# RL6845_IP_SVD register map
Vendor: Realtek
Registers are 32-bit, read-write, reset 0x0 unless marked. A register's access mark holds for its fields unless they carry their own. Offsets are from the block's base; [hi:lo] are bit positions; lines under a group give offsets from that group; {n}, {i} and the like mark numbered series.

## lp_aon
Base 0x41008000
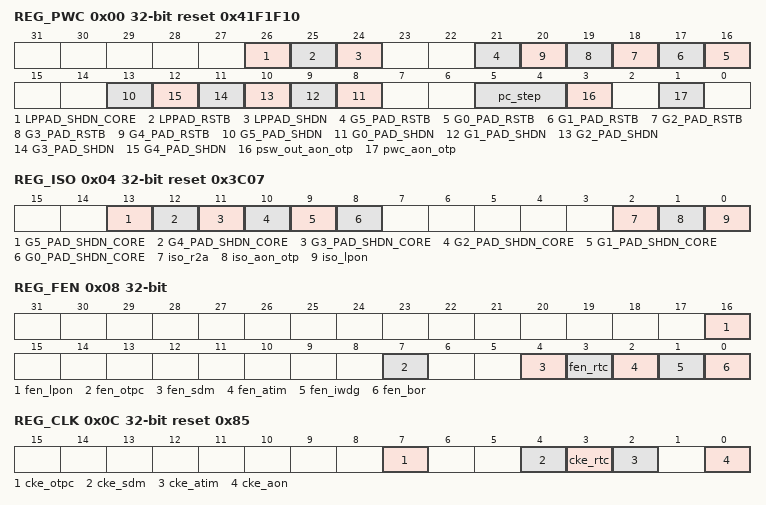
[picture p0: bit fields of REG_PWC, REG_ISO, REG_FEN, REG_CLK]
0x00 REG_PWC access per field reset 0x41F1F10
  [26] LPPAD_SHDN_CORE rw — 1: Release LP PAD SHDN CORE (except G5) 0: Global Assert LP PAD RSTB33 Note:G5 is aon pad, when all LP pad's IO power is ready , aon pmc will release this bit , only in power on init seq .
  [25] LPPAD_RSTB rw — 1: Release LP PAD RSTB33 (except G5) 0: Global Assert LP PAD RSTB33 Note: aon pmc will auto release this bit in power on init seq
  [24] LPPAD_SHDN rw — 1: Global Enable LP PAD (except G5) 0: Shutdown LP PAD Note: aon pmc will auto release this bit in power on init seq
  [21] G5_PAD_RSTB rw — 1: Enable G5 group pad 0: Reset PAD Note: This is AON pad group, direct connect to G5 pad, aon pmc will auto release this bit in power on init seq
  [n+16] G{n}_PAD_RSTB rw (n=0..4) — 1: Enable G{n} group pad 0: Reset PAD
  [13] G5_PAD_SHDN rw — 1: Enable G5 group pad 0: Shutdown PAD Note: This is AON pad group, aon pmc will auto release this bit in power on init seq
  [n+8] G{n}_PAD_SHDN rw (n=0..4) — 1: Enable G{n} group pad 0: Shutdown PAD
  [5:4] pc_step rw — power cut enable time step. 0: not valid 1: 10us 2: 20us 3: 30us
  [3] psw_out_aon_otp ro — aon otp domain power switch status 1: power on 0: power off
  [1] pwc_aon_otp rw — OTP power cut enable for core power, high active. 1:enable 0:disable
0x04 REG_ISO reset 0x3C07
  [13] G5_PAD_SHDN_CORE — 1: Enable G5 group pad 0: Shutdown PAD Note: This maybe nouse , for AON pad , IO power always on before core power.
  [12] G4_PAD_SHDN_CORE — 1: Enable G4 group pad 0: Shutdown PAD
  [11] G3_PAD_SHDN_CORE — 1: Enable G3 group pad 0: Shutdown PAD
  [10] G2_PAD_SHDN_CORE — 1: Enable G2 group pad 0: Shutdown PAD
  [9] G1_PAD_SHDN_CORE — 1: Enable G1 group pad 0: Shutdown PAD Note:default is shutdown, wait pmc enable MLDO power
  [8] G0_PAD_SHDN_CORE — 1: Enable G0 group pad 0: Shutdown PAD
  [2] iso_r2a — 1: ISO signals from RTC to AON 0: Release
  [1] iso_aon_otp — 1: ISO signals from otp core power domain 0: Release
  [0] iso_lpon — When LDO core power on, PD_LPON is on. 1: ISO signal of LPON power domain 0: Release
0x08 REG_FEN
  [16] fen_lpon — LS global reset 1: Enable LS function 0: Disable
  [7] fen_otpc — 1: Enable OTP function 0: Disable
  [4] fen_sdm — 1: Enable 32.768K SDM function 0: Disable
  [3] fen_rtc — 1: Enable RTC function 0: Disable
  [2] fen_atim — 1: Enable AON timer 0: Reset AON timer Note: AON timer starts to run only when event happens.
  [1] fen_iwdg — 1: Enable IWDG by HW autoload. Once enabled, IWDG can't be disabled unless por asserts.
  [0] fen_bor — Enable bor reset function, default is 0 when power on
0x0C REG_CLK reset 0x85
  [7] cke_otpc — 1: Enable OTPC clock 0: Disable Note: default change to 1 for osc4m req
  [4] cke_sdm — 1: Enable 32.768K SDM module's clock 0: Disable
  [3] cke_rtc — 1: Enable RTC clock 0: Disable
  [2] cke_atim — 1: Enable AON timer clock 0: Disable
  [0] cke_aon — if 0, AON clock will be gated except atim and debouce circuit. Note: AON clock can't be shutdown as analog need.
0x10 REG_CKSL
  [0] otpc_flg — This field is used to indicate OTP autoload field 1: ls 0:aon Note:because aon autoload only do once , so after power on , this bit will always be 1 . SW don't change this bit .
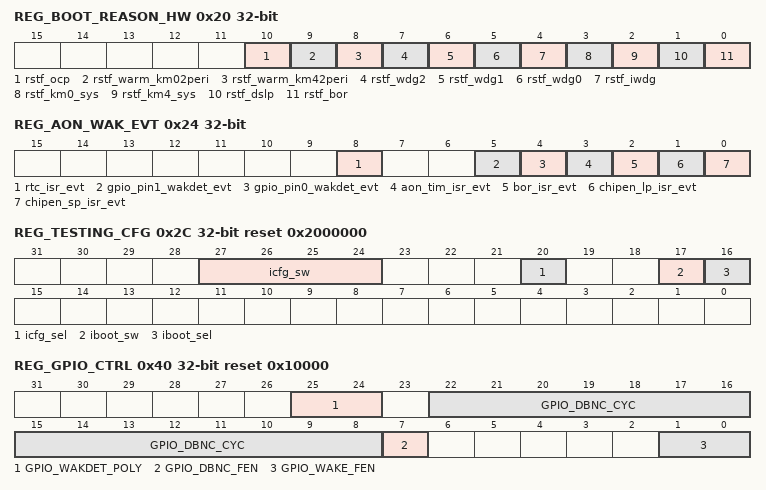
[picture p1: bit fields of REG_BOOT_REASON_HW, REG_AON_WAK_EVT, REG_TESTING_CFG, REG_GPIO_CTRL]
0x20 REG_BOOT_REASON_HW ro
  [10] rstf_ocp — This bit will be set to 1 when OCP happen, it will let system enter dslp mode. Write 1 to clear.
  [9] rstf_warm_km02peri — This bit will be set to 1 when KM0 warm resets the system. Write 1 to clear.
  [8] rstf_warm_km42peri — This bit will be set to 1 when km4 warm resets the system. Write 1 to clear.
  [7] rstf_wdg2 — This bit will be set to 1 when WDG resets the system. Write 1 to clear.
  [6] rstf_wdg1 — This bit will be set to 1 when WDG resets the system. Write 1 to clear.
  [5] rstf_wdg0 — This bit will be set to 1 when WDG resets the system. Write 1 to clear.
  [4] rstf_iwdg — This bit will be set to 1 when WDG resets the system. Write 1 to clear.
  [3] rstf_km0_sys — This bit will be set to 1 when KM0 resets the system. Write 1 to clear.
  [2] rstf_km4_sys — This bit will be set to 1 when KM4 resets the system. Write 1 to clear.
  [1] rstf_dslp — This is boot reason for dslp exit, clear by SW write to 1.
  [0] rstf_bor — This bit will be set to 1 when BOR resets the system. Write 1 to clear.
0x24 REG_AON_WAK_EVT ro
  [8] rtc_isr_evt — RTC interrupt wake event occurs.
  [5] gpio_pin1_wakdet_evt — Wake event for wake pin1 1: wake event detected 0: no wake event Note: aon gpio only used to wake hw pmc, to interrupt SW, it must enable GPIO interrupt in LP GPIO IP, and the poly must be same as AON GPIO setting.
  [4] gpio_pin0_wakdet_evt — Wake event for wake pin0 1: wake event detected 0: no wake event Note: aon gpio only used to wake hw pmc, to interrupt SW, it must enable GPIO interrupt in LP GPIO IP, and the poly must be same as AON GPIO setting.
  [3] aon_tim_isr_evt — AON timer interrupt event occurs.
  [2] bor_isr_evt — bor interrupt event occurs.
  [1] chipen_lp_isr_evt — Chipen long press interrupt event occurs.
  [0] chipen_sp_isr_evt — Chipen short press interrupt event occurs.
0x2C REG_TESTING_CFG reset 0x2000000
  [27:24] icfg_sw — icfg configured by SIC/SW
  [20] icfg_sel — If 1, using icfg_sw to replace trapped icfg value.
  [17] iboot_sw — iboot configured by SIC/SW
  [16] iboot_sel — If 1, using iboot_sw to replace trapped iboot value.
0x30 REG_TIM_CNT ro
  [31:0] aon_tim_cnt_cur — Aon timer current count value.
0x34 REG_TIM_SET
  [31:0] aon_tim_cnt_set — Set aon time a countdown value, when timer count down, it will trigger a aon_tim event.
0x38 REG_TIM_IER
  [0] AON_TIM_IE — Timer interrupt enable 0:disable 1:enable
0x3C REG_TIM_ISR ro
  [0] AON_TIM_ISR — Timer interrupt status 0:no interrupt 1:interrupt occurs
0x40 REG_GPIO_CTRL reset 0x10000
  [25:24] GPIO_WAKDET_POLY — Wake pin polarity 0: low active 1: high active bit1: wake pin1 polarity bit0: wake pin0 polarity Note: once a wake pin is set, the pads PU/PD will be force by this poly value, and soft config have no use.
  [22:8] GPIO_DBNC_CYC — The GPIO signal will be filtered by the number of debounce cycles of specified in this register. (100k/128k)
  [7] GPIO_DBNC_FEN — 1: Enable gpio debouncer function 0: Disable Default disable for simualtion issue
  [1:0] GPIO_WAKE_FEN — 1: Enable wake pin function 0: Disable Every GPIO has its own enable. When aon pmc is not in DSLP, wake pins will not effect PMC state althrougth this bit is set.
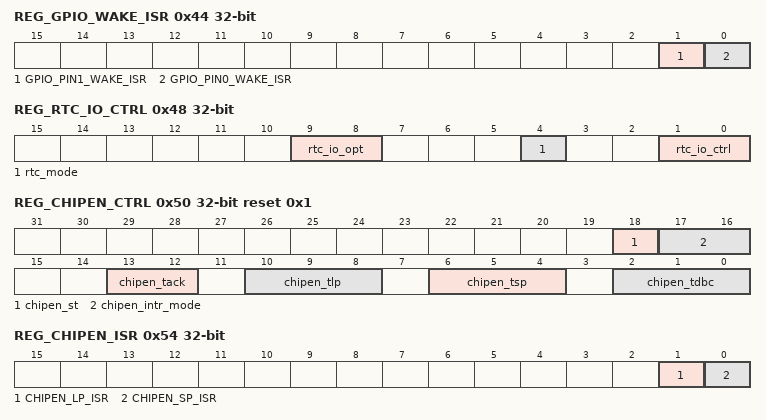
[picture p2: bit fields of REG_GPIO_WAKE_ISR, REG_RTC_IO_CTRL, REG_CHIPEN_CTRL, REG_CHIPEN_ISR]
0x44 REG_GPIO_WAKE_ISR ro
  [1] GPIO_PIN1_WAKE_ISR — Wake pin1 interrupt status 0:no interrupt 1:interrupt occurs
  [0] GPIO_PIN0_WAKE_ISR — Wake pin0 interrupt status 0:no interrupt 1:interrupt occurs
0x48 REG_RTC_IO_CTRL access per field
  [9:8] rtc_io_opt rw — RTC IO option register [0]: extend diode [1]: rsvd
  [4] rtc_mode ro — RTC IO mode flag 1: RTC IO domain enabled 0: disable
  [1:0] rtc_io_ctrl rw — RTC IO control mode 0: shift disable 1: shift enable 2: rtc mode (once enable , it can't be disabled) 3: iwdg feed
0x4C REG_IWDG_IO_DIS reset 0x1
  [0] iwdg_io_dis — IWDG IO disable . Default enabled in RTC domain . This bit is protected , and only can be accessed by OTP
0x50 REG_CHIPEN_CTRL access per field reset 0x1
  [18] chipen_st ro — CHIP_EN pin status 0: logic '0' on CHIP_EN pin 1: logic '1' on CHIP_EN pin
  [17:16] chipen_intr_mode rw — Chipen operation mode. 00: reset mode. When chipen pad low, hw will reset all chip 01: interrup mode. It will enable short/long press function. 1X: pulse reset mode. The transation from other value to 2'd2 will gen a posedge to set RST_PULSE_EN in HV domain. Once in pulse reset mode , this field can't be modified again , and always read out 2'b11
  [13:12] chipen_tack rw — 00: 50ms 01: 100ms 10: 200ms 11: 400ms
  [10:8] chipen_tlp rw — 000: 1000ms 001: 1500ms 010: 2000ms 011: 2500ms 100: 3000ms 101: 3500ms 110: 4000ms 111: 4500ms
  [6:4] chipen_tsp rw — 000: 0ms 001: 50ms 010: 100ms 011: 150ms 100: 200ms 101: 250ms 110: 300ms 111: 350ms
  [2:0] chipen_tdbc rw — 000: 0us 001: 100us 010: 500us 011: 1000us 100: 2000us 101: 4000us 110: 8000us 111: 16000us
0x54 REG_CHIPEN_ISR ro
  [1] CHIPEN_LP_ISR — chipen long press interrupt status 0:no interrupt 1:interrupt occurs
  [0] CHIPEN_SP_ISR — chipen short press interrupt status 0:no interrupt 1:interrupt occurs
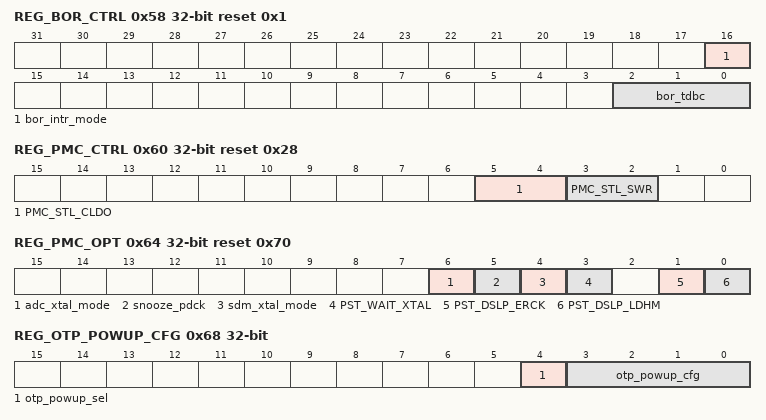
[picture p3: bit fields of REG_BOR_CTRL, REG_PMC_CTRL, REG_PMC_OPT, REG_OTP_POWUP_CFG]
0x58 REG_BOR_CTRL reset 0x1
  [16] bor_intr_mode — BOR operation mode. 0: reset mode. When analog detect bor, hw will trigger a bor reset. 1: interrup mode. It will raise an interrup first. If this bit set to 0, then trigger a bor reset.
  [2:0] bor_tdbc — 000: 0us 001: 100us 010: 500us 011: 1000us 100: 2000us 101: 4000us 110: 8000us 111: 16000us
0x5C REG_BOR_ISR ro
  [0] BOR_ISR — BOR interrupt status 0:no interrupt 1:interrupt occurs
0x60 REG_PMC_CTRL reset 0x28
  [5:4] PMC_STL_CLDO — wait time for core LDO stable 0: 8*T (T = 10us) 1: 16*T 2: 32*T 3: 64*T
  [3:2] PMC_STL_SWR — wait time for SWR stable 0: 64*T (T = 10us) 1: 128*T 2: 256*T 3: 512*T
0x64 REG_PMC_OPT reset 0x70
  [6] adc_xtal_mode — Select xtal mode when xtal used for adc/ctc/comp. 1: Normal 0: LPS
  [5] snooze_pdck — Select xtal auto pdck function for sdm calibration use xtal lps mode 1:Enable 0:Disable
  [4] sdm_xtal_mode — Select xtal mode when xtal used for sdm calibration. 1: Normal 0: LPS
  [3] PST_WAIT_XTAL — 1: When POF , polling xtal invalid signal and then run forward 0: not polling xtal invalid
  [1] PST_DSLP_ERCK — 1: Enable 100K clock for AON register access when PMC enter deep-sleep mode 0: Disable
  [0] PST_DSLP_LDHM — 1: Enable AON LDO enter into sleep mode when PMC enter deep-sleep mode 0: Disable
0x68 REG_OTP_POWUP_CFG
  [4] otp_powup_sel — select otp pow up flow is inside control or outside control 0: inside 1: outside
  [3:0] otp_powup_cfg — [0] : penvddr2 [1]: pldo [2]: pdstb [3]: ptrim
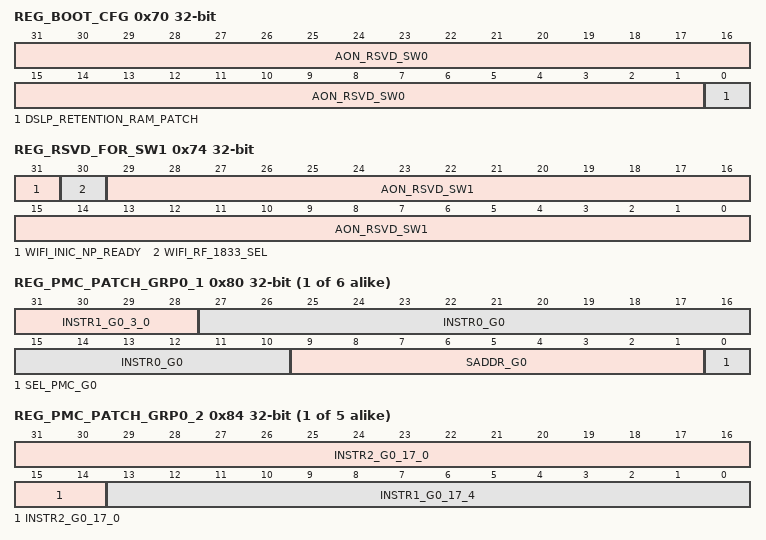
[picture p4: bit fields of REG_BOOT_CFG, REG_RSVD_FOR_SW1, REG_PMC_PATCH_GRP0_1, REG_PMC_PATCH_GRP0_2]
0x70 REG_BOOT_CFG
  [31:1] AON_RSVD_SW0
  [0] DSLP_RETENTION_RAM_PATCH — Deepsleep retention RAM patch
0x74 REG_RSVD_FOR_SW1
  [31] WIFI_INIC_NP_READY — Wi-Fi NP initialization ready flag
  [30] WIFI_RF_1833_SEL — Indication of RF voltage selection 0: 1.8V 1: 3.3V
  [29:0] AON_RSVD_SW1
{0x80+8i} REG_PMC_PATCH_GRP{i}_1 (i=0..5)
  [31:28] INSTR1_G{i}_3_0 — Instruction1 of AON PMC patch group{i}
  [27:10] INSTR0_G{i} — Instruction0 of AON PMC patch group{i}
  [9:1] SADDR_G{i} — Start address of the first instruction of AON PMC patch group0
  [0] SEL_PMC_G{i} — Select PMC for this patch group 0:aon pmc 1:regu pmc
{0x84+8i} REG_PMC_PATCH_GRP{i}_2 (i=0..4)
  [31:14] INSTR2_G{i}_17_0 — Instruction2 of AON PMC patch group{i}
  [13:0] INSTR1_G{i}_17_4 — Instruction1 of AON PMC patch group{i}
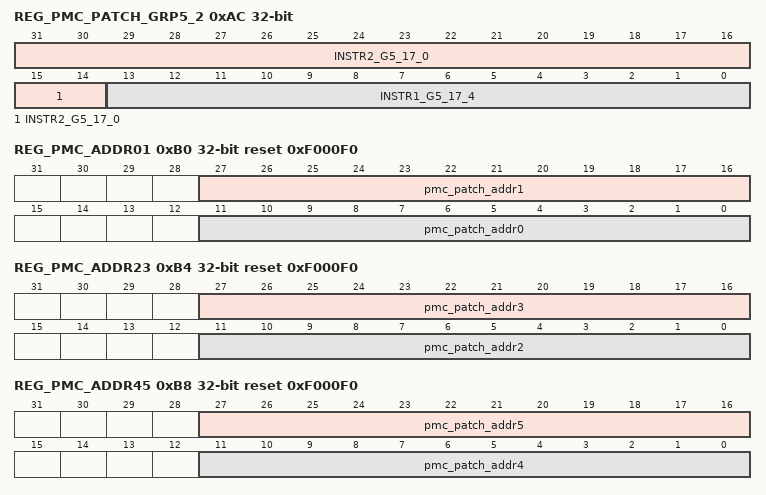
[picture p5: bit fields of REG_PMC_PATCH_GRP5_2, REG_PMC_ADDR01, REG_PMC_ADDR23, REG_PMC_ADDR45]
0xAC REG_PMC_PATCH_GRP5_2
  [31:14] INSTR2_G5_17_0 — HW used only , these are for pmc patch Note: regu reg 0xF0 must not be used
  [13:0] INSTR1_G5_17_4 — HW used only , these are for pmc patch
0xB0 REG_PMC_ADDR01 reset 0xF000F0
  [27:16] pmc_patch_addr1 — HW used only , these are for pmc patch
  [11:0] pmc_patch_addr0 — HW used only , these are for pmc patch
0xB4 REG_PMC_ADDR23 reset 0xF000F0
  [27:16] pmc_patch_addr3 — HW used only , these are for pmc patch
  [11:0] pmc_patch_addr2 — HW used only , these are for pmc patch
0xB8 REG_PMC_ADDR45 reset 0xF000F0
  [27:16] pmc_patch_addr5 — HW used only , these are for pmc patch
  [11:0] pmc_patch_addr4 — HW used only , these are for pmc patch
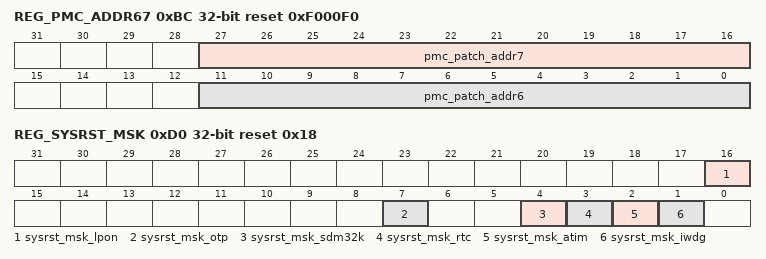
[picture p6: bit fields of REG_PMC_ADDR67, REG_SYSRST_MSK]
0xBC REG_PMC_ADDR67 reset 0xF000F0
  [27:16] pmc_patch_addr7 — HW used only , these are for pmc patch
  [11:0] pmc_patch_addr6 — HW used only , these are for pmc patch
0xC0 REG_RTC_IO_SOUT0 ro
  [31:0] rtc_io_test_dout_31_0 — Note , those bits are shared for RTC domain test used as shift in pattern
{0xC0+4i} REG_RTC_IO_SOUT{i} ro (i=1..3)
  [31:0] rtc_io_test_dout_{32i+31}_{32i}
0xD0 REG_SYSRST_MSK reset 0x18
  [16] sysrst_msk_lpon — LS global reset 1: mask LS reset when sys reset happen 0: reset by sys reset
  [7] sysrst_msk_otp — 1: mask OTP reset when sys reset happen 0: reset by sys reset
  [4] sysrst_msk_sdm32k — 1: mask 32.768K SDM reset when sys reset happen 0: reset by sys reset
  [3] sysrst_msk_rtc — 1: mask RTC reset when sys reset happen 0: reset by sys reset
  [2] sysrst_msk_atim — 1: mask AON timer 0: reset by sys reset OR warm reset Note: AON timer starts to run only when event happens.
  [1] sysrst_msk_iwdg — 1: mask AON IWDG reset 0: reset by sys reset OR warm reset
0xE0 REG_AON_BACKUP0
  [31:0] aon_bk0 — Note , those bits are shared for RTC domain test used as shift in pattern
{0xE0+4i} REG_AON_BACKUP{i} (i=1..3)
  [31:0] aon_bk{i}
0xF0 REG_BOUNDARY_CHK reset 0xBDC00512
  [31:0] dummy — HW used only . Used for access boundary check, AON is 256B which is 000-FF
0xF8 REG_DUMMY_AIP_CTRL0 reset 0xF
  [7:0] aip_ctrl_rsvd0 — reserved for aip control
0xFC REG_DUMMY_AIP_INFO0 ro
  [7:0] aip_info_rsvd0 — reserved for aip info indication
